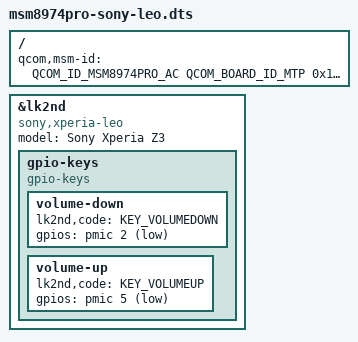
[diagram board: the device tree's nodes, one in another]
// SPDX-License-Identifier: GPL-2.0-only

#include <skeleton64.dtsi>
#include <lk2nd.dtsi>

/*
 * Because the bootloader uses parts of the dts to initialise the panel,
 * this isn't included with the other dts. To build, you need to add
 * LK2ND_QCDTBS="msm8974pro-sony-leo.dtb" to the build command.
 */

/ {
	qcom,msm-id = <QCOM_ID_MSM8974PRO_AC QCOM_BOARD_ID_MTP 0x10000>;
};

&lk2nd {
	model = "Sony Xperia Z3";
	compatible = "sony,xperia-leo";

	//FIXME: lk2nd,dtb-files = "msm8974pro-sony-leo";

	gpio-keys {
		compatible = "gpio-keys";

		volume-down {
			lk2nd,code = <KEY_VOLUMEDOWN>;
			gpios = <&pmic 2 (GPIO_ACTIVE_LOW | GPIO_PULL_UP)>;
		};

		volume-up {
			lk2nd,code = <KEY_VOLUMEUP>;
			gpios = <&pmic 5 (GPIO_ACTIVE_LOW | GPIO_PULL_UP)>;
		};
	};
};

#include "sony-leo/msm8974pro-ac-shinano_leo-display.dtsi"
